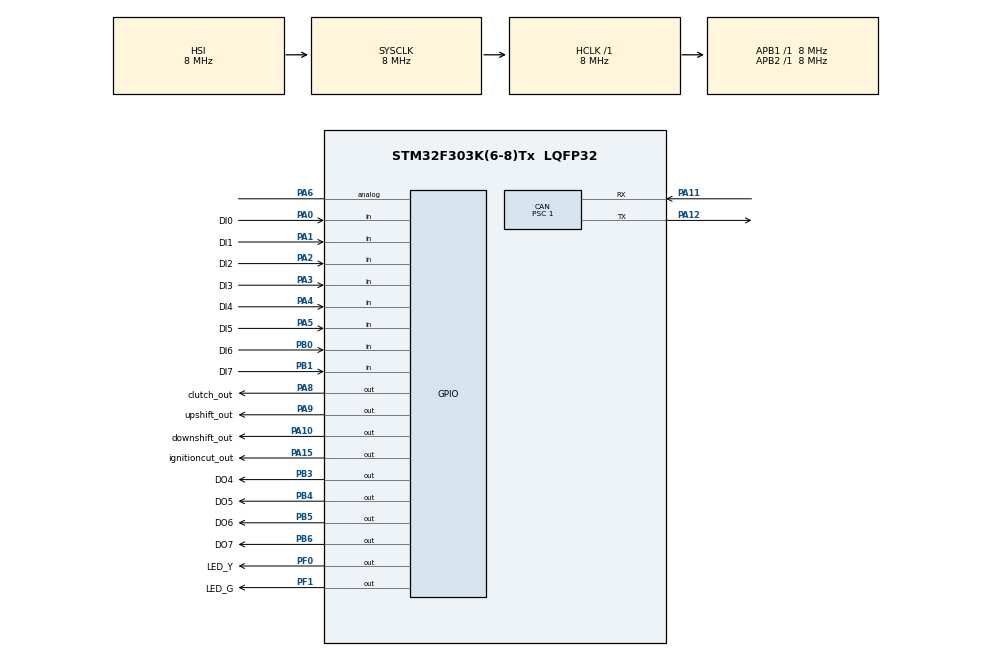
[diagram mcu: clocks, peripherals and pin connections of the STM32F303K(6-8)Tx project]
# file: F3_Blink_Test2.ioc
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CAN.BS1=CAN_BS1_13TQ
CAN.BS2=CAN_BS2_2TQ
CAN.CalculateTimeQuantum=125.0
CAN.Prescaler=1
FREERTOS.Tasks01=defaultTask,0,128,StartDefaultTask,Default,NULL,Dynamic,NULL,NULL;TaskSendCan,0,128,TaskSend,Default,NULL,Dynamic,NULL,NULL;TaskGetCan,-3,128,TaskGet,Default,NULL,Dynamic,NULL,NULL
Mcu.Family=STM32F3
Mcu.Name=STM32F303K(6-8)Tx
Mcu.Package=LQFP32
NVIC.CAN_RX0_IRQn=true\:5\:0\:false\:false\:true\:true\:true
NVIC.CAN_TX_IRQn=true\:5\:0\:false\:false\:true\:true\:true
NVIC.PriorityGroup=NVIC_PRIORITYGROUP_4
PA0.GPIO_Label=DI0
PA0.Signal=GPIO_Input
PA1.GPIO_Label=DI1
PA1.Signal=GPIO_Input
PA10.GPIO_Label=downshift_out
PA10.Signal=GPIO_Output
PA11.Mode=Master
PA11.Signal=CAN_RX
PA12.Mode=Master
PA12.Signal=CAN_TX
PA15.GPIO_Label=ignitioncut_out
PA15.Signal=GPIO_Output
PA2.GPIO_Label=DI2
PA2.Signal=GPIO_Input
PA3.GPIO_Label=DI3
PA3.Signal=GPIO_Input
PA4.GPIO_Label=DI4
PA4.Signal=GPIO_Input
PA5.GPIO_Label=DI5
PA5.Signal=GPIO_Input
PA6.Signal=GPIO_Analog
PA8.GPIO_Label=clutch_out
PA8.Signal=GPIO_Output
PA9.GPIO_Label=upshift_out
PA9.Signal=GPIO_Output
PB0.GPIO_Label=DI6
PB0.Signal=GPIO_Input
PB1.GPIO_Label=DI7
PB1.Signal=GPIO_Input
PB3.GPIO_Label=DO4
PB3.Signal=GPIO_Output
PB4.GPIO_Label=DO5
PB4.Signal=GPIO_Output
PB5.GPIO_Label=DO6
PB5.Signal=GPIO_Output
PB6.GPIO_Label=DO7
PB6.Signal=GPIO_Output
PF0\ /\ OSC_IN.GPIO_Label=LED_Y
PF0\ /\ OSC_IN.GPIO_ModeDefaultOutputPP=GPIO_MODE_OUTPUT_OD
PF0\ /\ OSC_IN.Signal=GPIO_Output
PF1\ /\ OSC_OUT.GPIO_Label=LED_G
PF1\ /\ OSC_OUT.GPIO_ModeDefaultOutputPP=GPIO_MODE_OUTPUT_OD
PF1\ /\ OSC_OUT.Signal=GPIO_Output
ProjectManager.HeapSize=0x200
ProjectManager.StackSize=0x400
ProjectManager.TargetToolchain=SW4STM32
RCC.AHBFreq_Value=8000000
RCC.APB1Freq_Value=8000000
RCC.APB1TimFreq_Value=8000000
RCC.APB2Freq_Value=8000000
RCC.APB2TimFreq_Value=8000000
RCC.CortexFreq_Value=8000000
RCC.DATA_CACHE_ENABLE=0
RCC.HCLKFreq_Value=8000000
RCC.HSE_VALUE=8000000
RCC.HSI_VALUE=8000000
RCC.INSTRUCTION_CACHE_ENABLE=0
RCC.SYSCLKFreq_VALUE=8000000
VP_FREERTOS_VS_ENABLE.Mode=Enabled
board=custom

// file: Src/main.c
/**
  ******************************************************************************
  * @file           : main.c
  * @brief          : Main program body
  ******************************************************************************
  * This notice applies to any and all portions of this file
  * that are not between comment pairs USER CODE BEGIN and
  * USER CODE END. Other portions of this file, whether
  * inserted by the user or by software development tools
  * are owned by their respective copyright owners.
  *
  * Copyright (c) 2019 STMicroelectronics International N.V.
  * All rights reserved.
  *
  * Redistribution and use in source and binary forms, with or without
  * modification, are permitted, provided that the following conditions are met:
  *
  * 1. Redistribution of source code must retain the above copyright notice,
  *    this list of conditions and the following disclaimer.
  * 2. Redistributions in binary form must reproduce the above copyright notice,
  *    this list of conditions and the following disclaimer in the documentation
  *    and/or other materials provided with the distribution.
  * 3. Neither the name of STMicroelectronics nor the names of other
  *    contributors to this software may be used to endorse or promote products
  *    derived from this software without specific written permission.
  * 4. This software, including modifications and/or derivative works of this
  *    software, must execute solely and exclusively on microcontroller or
  *    microprocessor devices manufactured by or for STMicroelectronics.
  * 5. Redistribution and use of this software other than as permitted under
  *    this license is void and will automatically terminate your rights under
  *    this license.
  *
  * THIS SOFTWARE IS PROVIDED BY STMICROELECTRONICS AND CONTRIBUTORS "AS IS"
  * AND ANY EXPRESS, IMPLIED OR STATUTORY WARRANTIES, INCLUDING, BUT NOT
  * LIMITED TO, THE IMPLIED WARRANTIES OF MERCHANTABILITY, FITNESS FOR A
  * PARTICULAR PURPOSE AND NON-INFRINGEMENT OF THIRD PARTY INTELLECTUAL PROPERTY
  * RIGHTS ARE DISCLAIMED TO THE FULLEST EXTENT PERMITTED BY LAW. IN NO EVENT
  * SHALL STMICROELECTRONICS OR CONTRIBUTORS BE LIABLE FOR ANY DIRECT, INDIRECT,
  * INCIDENTAL, SPECIAL, EXEMPLARY, OR CONSEQUENTIAL DAMAGES (INCLUDING, BUT NOT
  * LIMITED TO, PROCUREMENT OF SUBSTITUTE GOODS OR SERVICES; LOSS OF USE, DATA,
  * OR PROFITS; OR BUSINESS INTERRUPTION) HOWEVER CAUSED AND ON ANY THEORY OF
  * LIABILITY, WHETHER IN CONTRACT, STRICT LIABILITY, OR TORT (INCLUDING
  * NEGLIGENCE OR OTHERWISE) ARISING IN ANY WAY OUT OF THE USE OF THIS SOFTWARE,
  * EVEN IF ADVISED OF THE POSSIBILITY OF SUCH DAMAGE.
  *
  ******************************************************************************
  */
#include "main.h"
#include "stm32f3xx_hal.h"
#include "cmsis_os.h"
#include "can.h"
#include "gpio.h"

/* USER CODE BEGIN PV */
/* Private variables ---------------------------------------------------------*/

/* USER CODE END PV */

void SystemClock_Config(void);
void MX_FREERTOS_Init(void);

/* USER CODE BEGIN PFP */
/* Private function prototypes -----------------------------------------------*/

/* USER CODE END PFP */

int main(void)
{

  /* MCU Configuration----------------------------------------------------------*/

  /* Reset of all peripherals, Initializes the Flash interface and the Systick. */
  HAL_Init();

  /* Configure the system clock */
  SystemClock_Config();

  /* Initialize all configured peripherals */
  MX_GPIO_Init();
  MX_CAN_Init();
  /* USER CODE BEGIN 2 */
  JDO_CanInit();
  /* USER CODE END 2 */

  /* Call init function for freertos objects (in freertos.c) */
  MX_FREERTOS_Init();

  /* Start scheduler */
  osKernelStart();

  /* We should never get here as control is now taken by the scheduler */

  /* Infinite loop */
  /* USER CODE BEGIN WHILE */
  while (1)
  {
	  //HAL_GPIO_WritePin(LED_Green_GPIO_Port, LED_Green_Pin, GPIO_PIN_SET); //geänderte Zeile
	  	  	  	  	  	  	  	  	  	  	  	  	  	  	  	  	  	  //Wird nie ausgeführt
  /* USER CODE END WHILE */

  /* USER CODE BEGIN 3 */
	 //JDO_SendCan();
	 // HAL_Delay(100);
  }
  /* USER CODE END 3 */

}

void SystemClock_Config(void)
{

  RCC_OscInitTypeDef RCC_OscInitStruct;
  RCC_ClkInitTypeDef RCC_ClkInitStruct;

    /**Initializes the CPU, AHB and APB busses clocks
    */
  RCC_OscInitStruct.OscillatorType = RCC_OSCILLATORTYPE_HSI;
  RCC_OscInitStruct.HSIState = RCC_HSI_ON;
  RCC_OscInitStruct.HSICalibrationValue = 16;
  RCC_OscInitStruct.PLL.PLLState = RCC_PLL_NONE;
  if (HAL_RCC_OscConfig(&RCC_OscInitStruct) != HAL_OK)
  {
    _Error_Handler(__FILE__, __LINE__);
  }

    /**Initializes the CPU, AHB and APB busses clocks
    */
  RCC_ClkInitStruct.ClockType = RCC_CLOCKTYPE_HCLK|RCC_CLOCKTYPE_SYSCLK
                              |RCC_CLOCKTYPE_PCLK1|RCC_CLOCKTYPE_PCLK2;
  RCC_ClkInitStruct.SYSCLKSource = RCC_SYSCLKSOURCE_HSI;
  RCC_ClkInitStruct.AHBCLKDivider = RCC_SYSCLK_DIV1;
  RCC_ClkInitStruct.APB1CLKDivider = RCC_HCLK_DIV1;
  RCC_ClkInitStruct.APB2CLKDivider = RCC_HCLK_DIV1;

  if (HAL_RCC_ClockConfig(&RCC_ClkInitStruct, FLASH_LATENCY_0) != HAL_OK)
  {
    _Error_Handler(__FILE__, __LINE__);
  }

    /**Configure the Systick interrupt time
    */
  HAL_SYSTICK_Config(HAL_RCC_GetHCLKFreq()/1000);

    /**Configure the Systick
    */
  HAL_SYSTICK_CLKSourceConfig(SYSTICK_CLKSOURCE_HCLK);

  /* SysTick_IRQn interrupt configuration */
  HAL_NVIC_SetPriority(SysTick_IRQn, 15, 0);
}

void _Error_Handler(char *file, int line)
{
  while(1)
  {
  }
}

/************************ (C) COPYRIGHT STMicroelectronics *****END OF FILE****/

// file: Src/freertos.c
/* USER CODE BEGIN Header */
/**
  ******************************************************************************
  * File Name          : freertos.c
  * Description        : Code for freertos applications
  ******************************************************************************
  * This notice applies to any and all portions of this file
  * that are not between comment pairs USER CODE BEGIN and
  * USER CODE END. Other portions of this file, whether
  * inserted by the user or by software development tools
  * are owned by their respective copyright owners.
  *
  * Copyright (c) 2018 STMicroelectronics International N.V.
  * All rights reserved.
  *
  * Redistribution and use in source and binary forms, with or without
  * modification, are permitted, provided that the following conditions are met:
  *
  * 1. Redistribution of source code must retain the above copyright notice,
  *    this list of conditions and the following disclaimer.
  * 2. Redistributions in binary form must reproduce the above copyright notice,
  *    this list of conditions and the following disclaimer in the documentation
  *    and/or other materials provided with the distribution.
  * 3. Neither the name of STMicroelectronics nor the names of other
  *    contributors to this software may be used to endorse or promote products
  *    derived from this software without specific written permission.
  * 4. This software, including modifications and/or derivative works of this
  *    software, must execute solely and exclusively on microcontroller or
  *    microprocessor devices manufactured by or for STMicroelectronics.
  * 5. Redistribution and use of this software other than as permitted under
  *    this license is void and will automatically terminate your rights under
  *    this license.
  *
  * THIS SOFTWARE IS PROVIDED BY STMICROELECTRONICS AND CONTRIBUTORS "AS IS"
  * AND ANY EXPRESS, IMPLIED OR STATUTORY WARRANTIES, INCLUDING, BUT NOT
  * LIMITED TO, THE IMPLIED WARRANTIES OF MERCHANTABILITY, FITNESS FOR A
  * PARTICULAR PURPOSE AND NON-INFRINGEMENT OF THIRD PARTY INTELLECTUAL PROPERTY
  * RIGHTS ARE DISCLAIMED TO THE FULLEST EXTENT PERMITTED BY LAW. IN NO EVENT
  * SHALL STMICROELECTRONICS OR CONTRIBUTORS BE LIABLE FOR ANY DIRECT, INDIRECT,
  * INCIDENTAL, SPECIAL, EXEMPLARY, OR CONSEQUENTIAL DAMAGES (INCLUDING, BUT NOT
  * LIMITED TO, PROCUREMENT OF SUBSTITUTE GOODS OR SERVICES; LOSS OF USE, DATA,
  * OR PROFITS; OR BUSINESS INTERRUPTION) HOWEVER CAUSED AND ON ANY THEORY OF
  * LIABILITY, WHETHER IN CONTRACT, STRICT LIABILITY, OR TORT (INCLUDING
  * NEGLIGENCE OR OTHERWISE) ARISING IN ANY WAY OUT OF THE USE OF THIS SOFTWARE,
  * EVEN IF ADVISED OF THE POSSIBILITY OF SUCH DAMAGE.
  *
  ******************************************************************************
  */
/* USER CODE END Header */

#include "FreeRTOS.h"
#include "task.h"
#include "main.h"
#include "cmsis_os.h"
#include "can.h"

/* USER CODE BEGIN Variables */
volatile uint8_t nCM =0;
/* USER CODE END Variables */
osThreadId defaultTaskHandle;
osThreadId TaskSendCanHandle;
osThreadId TaskGetCanHandle;

/* USER CODE BEGIN FunctionPrototypes */
   void newCanMessage(void);
/* USER CODE END FunctionPrototypes */

void StartDefaultTask(void const * argument);
void TaskSend(void const * argument);
void TaskGet(void const * argument);

void MX_FREERTOS_Init(void); /* (MISRA C 2004 rule 8.1) */

void MX_FREERTOS_Init(void) {

  /* Create the thread(s) */
  /* definition and creation of defaultTask */
  osThreadDef(defaultTask, StartDefaultTask, osPriorityNormal, 0, 128);
  defaultTaskHandle = osThreadCreate(osThread(defaultTask), NULL);

#ifdef ph_debug
  /* definition and creation of TaskSendCan */
  osThreadDef(TaskSendCan, TaskSend, osPriorityNormal, 0, 128);
  TaskSendCanHandle = osThreadCreate(osThread(TaskSendCan), NULL);
#endif //ph_debug

  /* definition and creation of TaskGetCan */
  osThreadDef(TaskGetCan, TaskGet, osPriorityNormal, 0, 128);
  TaskGetCanHandle = osThreadCreate(osThread(TaskGetCan), NULL);

}

void StartDefaultTask(void const * argument)
{

  /* USER CODE BEGIN StartDefaultTask */
  /* Infinite loop */
  for(;;)
  {
  //  osDelay(500);
 //   JDO_SendCan();
 //   JDO_GetCan();
  }
  /* USER CODE END StartDefaultTask */
}

void TaskSend(void const * argument)
{
  /* USER CODE BEGIN TaskSend */
  /* Infinite loop */
#ifdef ph_debug
  for(;;)
  {
	  osDelay(500);
	  JDO_SendCan();
  }
#endif //debug
  /* USER CODE END TaskSend */
}

void TaskGet(void const * argument)
{
  /* USER CODE BEGIN TaskGet */
  /* Infinite loop */
  for(;;)
  {
	  osDelay(1);
	  if(nCM == 1){
		  JDO_GetCan();
	  }
	  nCM =0;
  }
  /* USER CODE END TaskGet */
}

/* USER CODE BEGIN Application */
void newCanMessage(void){
	   nCM = 1;
}
/* USER CODE END Application */

/************************ (C) COPYRIGHT STMicroelectronics *****END OF FILE****/
